# dm64lc_cslr_pll1_001 register map
Vendor: Texas Instruments
Peripheral module from a debugger description file.
Registers are 32-bit, access not given, reset 0x0 unless marked. A register's access mark holds for its fields unless they carry their own. Offsets are as the file gives them; lines under a group give offsets from that group; [hi:lo] are bit positions; {n}, {i} and the like mark numbered series; 'fields as' and 'values as' point back to an identical list; <NAME> marks a mode.

## PLL_1 — PLL 1 Module
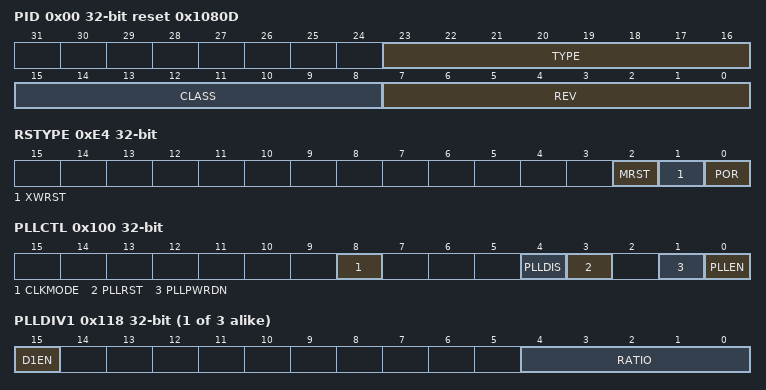
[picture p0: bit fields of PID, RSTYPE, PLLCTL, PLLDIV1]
0x00 PID reset 0x1080D — Peripheral ID Register
  [23:16] TYPE ro — Peripheral type
  [15:8] CLASS ro — Peripheral class
  [7:0] REV ro — Peripheral revision
0xE4 RSTYPE — Reset Type Status Register
  [2] MRST ro — Maximum reset. If 1, maximum reset was the reset to occur that is of highest priority
  [1] XWRST ro — External warm reset. If 1, warm reset (RESET) was the last reset to occur that is of highest priority.
  [0] POR ro — Power on reset. If 1, power on reset (POR) was the last reset to occur that is of highest priority.
0x100 PLLCTL — PLL Control Register
  [8] CLKMODE rw — Reference Clock Selection; Actual default determined by module tie-off (0-OSCIN), (1-CLKIN, CLKIN Square wave)
    0=OSCIN (Internal Oscillator); 1=CLKIN (CLKIN Square Wave)
  [4] PLLDIS rw — PLL enable/disable
    0=ENABLE (PLL Enabled); 1=DISABLE (PLL Disabled)
  [3] PLLRST rw — PLL reset
    0=PLL_IN_RESET (PLL reset asserted); 1=PLL_NOT_IN_RESET (PLL reset not asserted)
  [1] PLLPWRDN rw — PLL Power down
    0=POWERED_DOWN (PLL is powered down, no PLL operation); 1=POWERED_UP (PLL is powered up)
  [0] PLLEN rw — PLL mode enable
    0=BYPASS_MODE (PLL is operating in bypass mode); 1=PLL_MODE (PLL is operating in PLL mode)
0x110 PLLM — PLL Multiplier Register
  [5:0] PLLM rw — PLL multiplier
{0x114+4i} PLLDIV{i} (i=1..3) — PLL Controller Divider Register {i}
  [15] D{i}EN rw — PLL divider {i} enable/disable
    0=DISABLED (Divider {i} disabled); 1=ENABLED (Divider {i} enabled)
  [4:0] RATIO rw — Divide by ratio
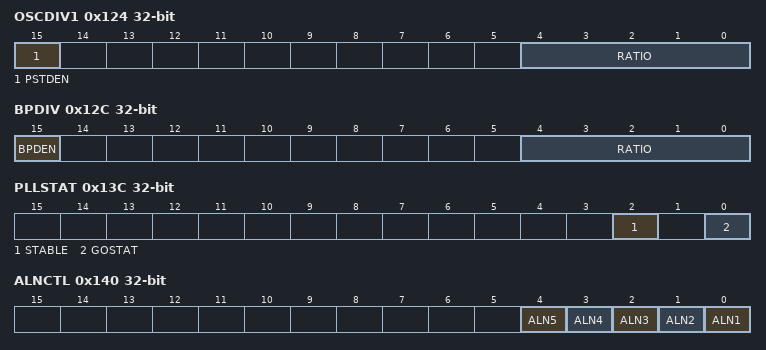
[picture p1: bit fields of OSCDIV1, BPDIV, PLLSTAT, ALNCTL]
0x124 OSCDIV1 — PLL Post-Divider Control Register
  [15] PSTDEN rw — PLL Post dvider enable/disable
    0=DISABLED (Post divider disabled)
  [4:0] RATIO rw — Divide by ratio
0x12C BPDIV — PLL Bypass Divider Register
  [15] BPDEN rw — PLL Bypass divider enabe/disable
    0=DISABLED (Bypass divider disabled)
  [4:0] RATIO rw — Divide by ratio
0x138 PLLCMD — PLL Controller Command Register
  [0] GOSET rw — GO bit for syscllk phase alignment
    0=CLEAR_BIT (Clears bit, has no effect); 1=SET_PHASE_ALIGNMENT (Sets clock phase alignment)
0x13C PLLSTAT — PLL Controller Status Register
  [2] STABLE ro — OSC counter done, oscillator assumedto be stable. This bit shold be 1 by time device comes out of reset.
    0=OSC_NOT_STABLE (OSC count not done, oscillator may not be stable); 1=OSC_STABLE (OSC count is done, oscilator assumed stable)
  [0] GOSTAT ro — Stauts of GO operation, If 1, go operation is still in progress.0 indicates GO not in progress
    0=GO_NOT_IN_PROGRESS (GO operation not in progress); 1=GO_IN_PROGRESS (GO operation in progess)
0x140 ALNCTL — PLL Controller Clock Align Register
  [all] fields
    0=NOT_ALIGNED (Clock not aligned with other system clocks); 1=ALIGNED (Clock aligned with other system clocks)
  [n-1] ALN{n} rw (n=1..5) — Align sysclk{n} with other system clocks chosen in align register
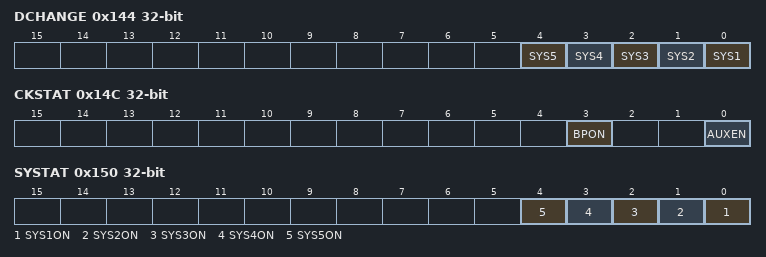
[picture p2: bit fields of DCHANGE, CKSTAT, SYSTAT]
0x144 DCHANGE — PLLDIV Ratio Change Status Register
  [all] fields
    0=NOT_MODIFIED (Sysclk ratio has not been modified); 1=MODIFIED (Sysclk ratio has been modified)
  [n-1] SYS{n} rw (n=1..5) — Sysclk{n} divide ratio is modified
0x148 CKEN — PLLDIV Ratio Change Status Register
  [0] AUXEN rw — AUXCLK enable/disable
    0=AUXCLK_DISABLED; 1=AUXCLK_ENABLED
0x14C CKSTAT — PLLDIV Ratio Change Status Register
  [3] BPON ro — SYSCLKB status
    0=OFF (SYSCLKB is off); 1=ON (SYSCLKB is on)
  [0] AUXEN ro — AUXCLK status
    0=OFF (AUXCLK is off); 1=ON (AUXCLK is on)
0x150 SYSTAT — PLLDIV Ratio Change Status Register
  [all] fields
    0=OFF (Sysclk is off); 1=ON (Sysclk is on)
  [n-1] SYS{n}ON ro (n=1..5) — Sysclk{n} status
